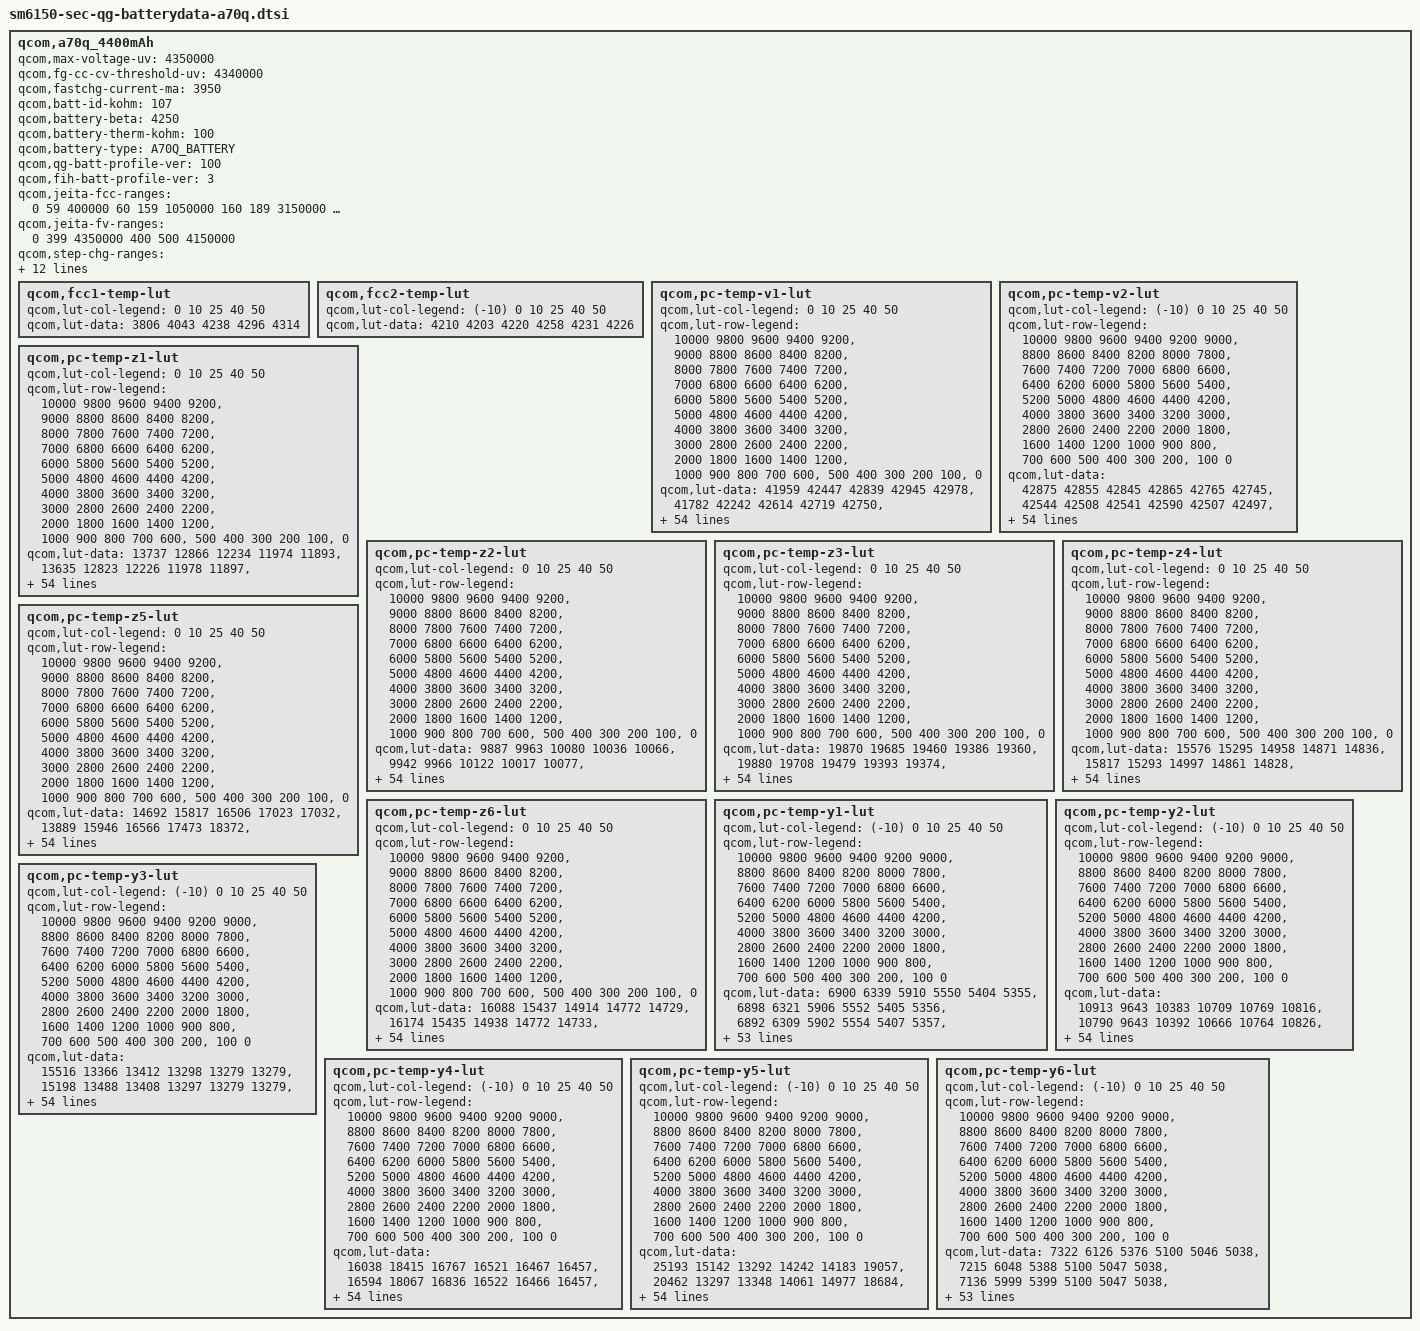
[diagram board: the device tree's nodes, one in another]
/*
 * Copyright (c) 2018, The Linux Foundation. All rights reserved.
 *
 * This program is free software; you can redistribute it and/or modify
 * it under the terms of the GNU General Public License version 2 and
 * only version 2 as published by the Free Software Foundation.
 *
 * This program is distributed in the hope that it will be useful,
 * but WITHOUT ANY WARRANTY; without even the implied warranty of
 * MERCHANTABILITY or FITNESS FOR A PARTICULAR PURPOSE.  See the
 * GNU General Public License for more details.
 */

qcom,a70q_4400mAh {
	/* A70Q BATTERY */
	qcom,max-voltage-uv = <4350000>;
	qcom,fg-cc-cv-threshold-uv = <4340000>;
	qcom,fastchg-current-ma = <3950>;
	qcom,batt-id-kohm = <107>;
	qcom,battery-beta = <4250>;
	qcom,battery-therm-kohm = <100>;
	qcom,battery-type = "A70Q_BATTERY";
	qcom,qg-batt-profile-ver = <100>;
	qcom,fih-batt-profile-ver = <3>;

	qcom,jeita-fcc-ranges = <0  59   400000
				60  159  1050000
				160 189  3150000
				190 399  3950000
				400 490  1550000>;

	qcom,jeita-fv-ranges = <0   399  4350000
				400 500  4150000>;

	qcom,step-chg-ranges = <3500000  4219999  3950000
				4220000  4350000  3150000>;
	qcom,vbat-avg-based-step-chg;
	qcom,taper-fcc;

	/* COOL = 18 DegC, WARM = 41 DegC */
	qcom,jeita-soft-thresholds = <0x4205 0x24EC>;
	/* COLD = 0 DegC, HOT = 50 DegC */
	qcom,jeita-hard-thresholds = <0x57F0 0x1C52>;

	qcom,qg-batt-aging-enable;
	qcom,vfloat-ranges = <0 299 4350000
				300 399 4330000
				400 699 4310000
				700 999 4290000
				1000 9999 4240000>;

	qcom,vbat-rechg-ranges = <0 299 4280000
				300 399 4260000
				400 699 4240000
				700 999 4220000
				1000 9999 4170000>;

	qcom,full-condition-soc-ranges = <0 299 93
				300 399 92
				400 699 91
				700 999 90
				1000 9999 89>;

	qcom,fcc1-temp-lut {
		qcom,lut-col-legend = <0 10 25 40 50>;
		qcom,lut-data = <3806 4043 4238 4296 4314>;
	};

	qcom,fcc2-temp-lut {
		qcom,lut-col-legend = <(-10) 0 10 25 40 50>;
		qcom,lut-data = <4210 4203 4220 4258 4231 4226>;
	};

	qcom,pc-temp-v1-lut {
		qcom,lut-col-legend = <0 10 25 40 50>;
		qcom,lut-row-legend = <10000 9800 9600 9400 9200>,
			<9000 8800 8600 8400 8200>,
			<8000 7800 7600 7400 7200>,
			<7000 6800 6600 6400 6200>,
			<6000 5800 5600 5400 5200>,
			<5000 4800 4600 4400 4200>,
			<4000 3800 3600 3400 3200>,
			<3000 2800 2600 2400 2200>,
			<2000 1800 1600 1400 1200>,
			<1000 900 800 700 600>,
			<500 400 300 200 100>,
			<0>;
		qcom,lut-data = <41959 42447 42839 42945 42978>,
			<41782 42242 42614 42719 42750>,
			<41605 42051 42393 42496 42527>,
			<41430 41866 42178 42277 42309>,
			<41272 41682 41975 42062 42094>,
			<41142 41495 41781 41853 41882>,
			<41010 41316 41590 41649 41673>,
			<40823 41160 41392 41445 41467>,
			<40498 41034 41201 41241 41260>,
			<40160 40886 41036 41051 41060>,
			<39964 40632 40896 40892 40881>,
			<39846 40279 40734 40742 40713>,
			<39750 40020 40462 40549 40533>,
			<39657 39890 40137 40280 40326>,
			<39574 39792 39938 40041 40124>,
			<39491 39699 39838 39900 39960>,
			<39398 39614 39751 39796 39820>,
			<39298 39525 39642 39679 39682>,
			<39197 39409 39522 39550 39549>,
			<39093 39263 39372 39406 39411>,
			<38987 39103 39143 39217 39232>,
			<38886 38914 38900 38983 39005>,
			<38791 38712 38754 38799 38813>,
			<38701 38582 38658 38678 38681>,
			<38615 38512 38575 38578 38573>,
			<38531 38461 38493 38485 38477>,
			<38450 38413 38417 38400 38390>,
			<38389 38370 38349 38323 38311>,
			<38343 38332 38287 38252 38237>,
			<38306 38298 38230 38187 38169>,
			<38278 38266 38181 38131 38109>,
			<38257 38238 38136 38080 38057>,
			<38239 38211 38097 38033 38008>,
			<38220 38187 38065 37994 37962>,
			<38203 38163 38036 37958 37919>,
			<38182 38142 38004 37917 37871>,
			<38151 38117 37973 37873 37818>,
			<38102 38074 37934 37823 37758>,
			<38036 37998 37872 37756 37687>,
			<37953 37906 37787 37672 37603>,
			<37839 37806 37692 37578 37507>,
			<37711 37688 37582 37469 37394>,
			<37565 37548 37453 37343 37265>,
			<37430 37396 37300 37188 37110>,
			<37320 37270 37170 37066 36996>,
			<37266 37192 37089 36989 36925>,
			<37275 37172 37067 36967 36905>,
			<37247 37151 37051 36953 36889>,
			<37221 37128 37032 36935 36870>,
			<37132 37062 36987 36886 36815>,
			<36846 36834 36767 36638 36540>,
			<36403 36395 36332 36205 36109>,
			<35851 35839 35775 35647 35549>,
			<35128 35098 35023 34888 34788>,
			<33884 33898 33847 33712 33611>,
			<30000 30000 30000 30000 30000>;
	};

	qcom,pc-temp-v2-lut {
		qcom,lut-col-legend = <(-10) 0 10 25 40 50>;
		qcom,lut-row-legend = <10000 9800 9600 9400 9200 9000>,
			<8800 8600 8400 8200 8000 7800>,
			<7600 7400 7200 7000 6800 6600>,
			<6400 6200 6000 5800 5600 5400>,
			<5200 5000 4800 4600 4400 4200>,
			<4000 3800 3600 3400 3200 3000>,
			<2800 2600 2400 2200 2000 1800>,
			<1600 1400 1200 1000 900 800>,
			<700 600 500 400 300 200>,
			<100 0>;
		qcom,lut-data = <42875 42855 42845 42865 42765 42745>,
			<42544 42508 42541 42590 42507 42497>,
			<42243 42183 42262 42333 42263 42260>,
			<41971 41871 42012 42098 42035 42034>,
			<41705 41526 41790 41884 41822 41820>,
			<41504 41298 41580 41677 41616 41612>,
			<41414 41268 41364 41464 41407 41405>,
			<41362 41258 41150 41253 41199 41201>,
			<41255 41231 40972 41067 41007 41005>,
			<40701 40914 40851 40922 40844 40816>,
			<40038 40439 40727 40770 40680 40630>,
			<39824 40122 40497 40544 40470 40433>,
			<39754 39879 40103 40240 40208 40225>,
			<39672 39686 39797 39998 39992 40040>,
			<39508 39548 39676 39848 39862 39893>,
			<39281 39434 39590 39726 39756 39763>,
			<39032 39306 39480 39610 39635 39628>,
			<38712 39164 39341 39504 39503 39493>,
			<38449 38998 39184 39384 39356 39346>,
			<38349 38754 39003 39210 39173 39166>,
			<38292 38424 38800 38998 38959 38956>,
			<38244 38216 38626 38809 38773 38772>,
			<38199 38144 38488 38640 38619 38620>,
			<38158 38096 38367 38494 38486 38488>,
			<38117 38055 38262 38383 38378 38379>,
			<38078 38019 38169 38291 38288 38288>,
			<38038 37987 38084 38208 38206 38204>,
			<37998 37958 38000 38132 38130 38127>,
			<37958 37929 37926 38061 38059 38055>,
			<37918 37899 37880 37996 37996 37990>,
			<37880 37868 37853 37935 37940 37932>,
			<37842 37837 37830 37880 37887 37877>,
			<37800 37804 37805 37831 37836 37825>,
			<37756 37768 37776 37786 37784 37775>,
			<37710 37730 37744 37741 37725 37712>,
			<37661 37689 37703 37699 37648 37615>,
			<37609 37642 37657 37652 37565 37508>,
			<37552 37588 37603 37593 37491 37423>,
			<37488 37522 37536 37523 37423 37353>,
			<37418 37449 37459 37448 37350 37281>,
			<37338 37369 37368 37368 37268 37198>,
			<37249 37279 37263 37276 37174 37106>,
			<37165 37184 37157 37156 37061 36997>,
			<37090 37081 37052 37014 36920 36859>,
			<37015 36978 36955 36923 36841 36782>,
			<36940 36882 36874 36873 36811 36756>,
			<36899 36834 36835 36856 36797 36744>,
			<36851 36784 36793 36838 36781 36728>,
			<36789 36725 36739 36808 36750 36697>,
			<36688 36633 36650 36742 36665 36584>,
			<36490 36449 36461 36529 36361 36259>,
			<36130 36113 36099 36083 35891 35776>,
			<35582 35592 35542 35490 35276 35150>,
			<34791 34837 34763 34688 34429 34282>,
			<33566 33623 33591 33442 33201 33031>,
			<28481 28300 28229 28279 28273 28212>;
	};

	qcom,pc-temp-z1-lut {
		qcom,lut-col-legend = <0 10 25 40 50>;
		qcom,lut-row-legend = <10000 9800 9600 9400 9200>,
			<9000 8800 8600 8400 8200>,
			<8000 7800 7600 7400 7200>,
			<7000 6800 6600 6400 6200>,
			<6000 5800 5600 5400 5200>,
			<5000 4800 4600 4400 4200>,
			<4000 3800 3600 3400 3200>,
			<3000 2800 2600 2400 2200>,
			<2000 1800 1600 1400 1200>,
			<1000 900 800 700 600>,
			<500 400 300 200 100>,
			<0>;
		qcom,lut-data = <13737 12866 12234 11974 11893>,
			<13635 12823 12226 11978 11897>,
			<13620 12826 12224 11976 11898>,
			<13612 12837 12223 11974 11899>,
			<13607 12841 12221 11973 11900>,
			<13604 12836 12219 11974 11901>,
			<13602 12827 12219 11974 11901>,
			<13592 12822 12221 11974 11901>,
			<13558 12821 12223 11974 11901>,
			<13522 12820 12223 11973 11901>,
			<13508 12813 12218 11972 11900>,
			<13502 12802 12213 11969 11898>,
			<13498 12796 12208 11966 11897>,
			<13500 12796 12202 11962 11896>,
			<13513 12797 12201 11960 11896>,
			<13529 12800 12205 11961 11896>,
			<13545 12812 12210 11965 11898>,
			<13564 12824 12215 11967 11899>,
			<13578 12830 12219 11969 11900>,
			<13582 12834 12222 11970 11902>,
			<13584 12838 12224 11972 11903>,
			<13586 12845 12226 11974 11905>,
			<13590 12855 12230 11977 11907>,
			<13597 12861 12236 11980 11910>,
			<13603 12866 12241 11983 11913>,
			<13608 12870 12244 11986 11916>,
			<13614 12872 12247 11989 11918>,
			<13621 12876 12251 11993 11920>,
			<13633 12878 12256 11996 11922>,
			<13644 12878 12260 11999 11925>,
			<13649 12878 12263 12002 11927>,
			<13648 12879 12266 12005 11929>,
			<13646 12882 12268 12008 11932>,
			<13647 12886 12269 12011 11934>,
			<13653 12892 12271 12014 11937>,
			<13661 12906 12273 12017 11940>,
			<13675 12918 12275 12019 11943>,
			<13708 12921 12279 12022 11946>,
			<13738 12922 12283 12025 11948>,
			<13741 12923 12287 12029 11951>,
			<13728 12926 12291 12032 11954>,
			<13713 12931 12296 12035 11957>,
			<13683 12940 12301 12038 11960>,
			<13675 12949 12306 12042 11962>,
			<13689 12951 12312 12044 11964>,
			<13676 12953 12311 12046 11964>,
			<13665 12951 12317 12045 11964>,
			<13678 12947 12309 12046 11965>,
			<13684 12949 12310 12049 11966>,
			<13684 12950 12316 12052 11970>,
			<13708 12966 12321 12058 11977>,
			<13722 12985 12332 12069 11986>,
			<13717 12989 12347 12080 11996>,
			<13719 13025 12376 12098 12012>,
			<13719 13025 12376 12098 12012>,
			<13719 13025 12376 12098 12012>;
	};

	qcom,pc-temp-z2-lut {
		qcom,lut-col-legend = <0 10 25 40 50>;
		qcom,lut-row-legend = <10000 9800 9600 9400 9200>,
			<9000 8800 8600 8400 8200>,
			<8000 7800 7600 7400 7200>,
			<7000 6800 6600 6400 6200>,
			<6000 5800 5600 5400 5200>,
			<5000 4800 4600 4400 4200>,
			<4000 3800 3600 3400 3200>,
			<3000 2800 2600 2400 2200>,
			<2000 1800 1600 1400 1200>,
			<1000 900 800 700 600>,
			<500 400 300 200 100>,
			<0>;
		qcom,lut-data = <9887 9963 10080 10036 10066>,
			<9942 9966 10122 10017 10077>,
			<9963 9968 10133 10021 10073>,
			<9977 9970 10144 10031 10059>,
			<9980 9972 10300 10034 10052>,
			<9969 9975 10734 10030 10054>,
			<9953 9980 10995 10026 10060>,
			<9947 9985 11036 10027 10067>,
			<9950 9994 11057 10030 10073>,
			<9953 10003 11045 10035 10078>,
			<9950 10019 10978 10047 10080>,
			<9936 10039 10913 10064 10087>,
			<9921 10050 10902 10067 10095>,
			<9915 10052 10846 10053 10103>,
			<9910 10053 10727 10040 10111>,
			<9907 10062 10376 10056 10116>,
			<9908 10093 10098 10092 10121>,
			<9915 10134 10106 10109 10127>,
			<9924 10169 10163 10113 10136>,
			<9938 10204 10223 10117 10148>,
			<9958 10233 10285 10147 10163>,
			<9978 10254 10335 10217 10186>,
			<9994 10272 10334 10248 10197>,
			<10009 10277 10287 10200 10186>,
			<10026 10273 10254 10129 10159>,
			<10046 10267 10259 10091 10125>,
			<10067 10262 10267 10066 10063>,
			<10081 10258 10268 10051 10025>,
			<10090 10256 10264 10046 10025>,
			<10097 10257 10261 10044 10027>,
			<10105 10262 10265 10048 10030>,
			<10113 10268 10274 10059 10034>,
			<10121 10277 10285 10075 10042>,
			<10132 10289 10302 10098 10058>,
			<10147 10300 10323 10128 10089>,
			<10163 10309 10342 10158 10124>,
			<10181 10319 10362 10188 10175>,
			<10204 10332 10380 10215 10215>,
			<10223 10349 10400 10243 10224>,
			<10230 10359 10419 10277 10230>,
			<10232 10353 10422 10293 10232>,
			<10235 10340 10410 10287 10228>,
			<10238 10335 10402 10279 10225>,
			<10271 10333 10399 10274 10229>,
			<10306 10384 10407 10279 10225>,
			<10057 10377 10396 10267 10210>,
			<9392 10373 10375 10258 10215>,
			<9394 10373 10363 10276 10222>,
			<9469 10378 10360 10282 10225>,
			<9471 10398 10367 10324 10297>,
			<9740 10400 10386 10273 10143>,
			<9904 10347 10313 10175 10061>,
			<9751 10299 10272 10136 10021>,
			<9389 10237 10198 10083 9975>,
			<9389 10237 10198 10083 9975>,
			<9389 10237 10198 10083 9975>;
	};

	qcom,pc-temp-z3-lut {
		qcom,lut-col-legend = <0 10 25 40 50>;
		qcom,lut-row-legend = <10000 9800 9600 9400 9200>,
			<9000 8800 8600 8400 8200>,
			<8000 7800 7600 7400 7200>,
			<7000 6800 6600 6400 6200>,
			<6000 5800 5600 5400 5200>,
			<5000 4800 4600 4400 4200>,
			<4000 3800 3600 3400 3200>,
			<3000 2800 2600 2400 2200>,
			<2000 1800 1600 1400 1200>,
			<1000 900 800 700 600>,
			<500 400 300 200 100>,
			<0>;
		qcom,lut-data = <19870 19685 19460 19386 19360>,
			<19880 19708 19479 19393 19374>,
			<19872 19703 19482 19398 19379>,
			<19860 19689 19485 19402 19383>,
			<19844 19678 19492 19403 19385>,
			<19806 19671 19503 19399 19383>,
			<19763 19663 19509 19393 19377>,
			<19749 19647 19507 19390 19374>,
			<19750 19612 19503 19390 19373>,
			<19752 19586 19498 19389 19372>,
			<19746 19591 19490 19383 19368>,
			<19720 19609 19484 19373 19361>,
			<19689 19618 19482 19372 19359>,
			<19672 19605 19480 19382 19361>,
			<19658 19580 19472 19389 19364>,
			<19650 19561 19438 19382 19362>,
			<19653 19543 19409 19367 19357>,
			<19668 19531 19408 19362 19354>,
			<19684 19534 19414 19362 19352>,
			<19696 19552 19423 19363 19350>,
			<19708 19568 19440 19368 19351>,
			<19715 19579 19457 19378 19358>,
			<19714 19587 19458 19385 19367>,
			<19712 19590 19446 19390 19380>,
			<19712 19588 19438 19394 19394>,
			<19713 19584 19444 19396 19396>,
			<19715 19581 19455 19398 19392>,
			<19716 19579 19460 19399 19389>,
			<19712 19577 19462 19398 19386>,
			<19703 19575 19463 19396 19384>,
			<19694 19573 19463 19394 19380>,
			<19684 19571 19460 19392 19374>,
			<19674 19569 19457 19389 19368>,
			<19664 19567 19453 19384 19362>,
			<19655 19565 19450 19379 19356>,
			<19647 19561 19447 19376 19354>,
			<19640 19556 19444 19373 19353>,
			<19635 19553 19442 19372 19353>,
			<19631 19551 19440 19372 19353>,
			<19626 19548 19438 19374 19355>,
			<19622 19545 19436 19375 19357>,
			<19618 19542 19433 19372 19359>,
			<19615 19537 19430 19370 19361>,
			<19590 19530 19425 19372 19364>,
			<19555 19496 19414 19365 19359>,
			<19483 19493 19411 19361 19353>,
			<19288 19484 19407 19359 19342>,
			<19287 19482 19399 19352 19339>,
			<19274 19482 19398 19349 19337>,
			<19274 19477 19393 19345 19329>,
			<19380 19476 19393 19358 19356>,
			<19466 19486 19397 19367 19361>,
			<19457 19488 19403 19367 19361>,
			<19361 19469 19406 19368 19361>,
			<19361 19469 19406 19368 19361>,
			<19361 19469 19406 19368 19361>;
	};

	qcom,pc-temp-z4-lut {
		qcom,lut-col-legend = <0 10 25 40 50>;
		qcom,lut-row-legend = <10000 9800 9600 9400 9200>,
			<9000 8800 8600 8400 8200>,
			<8000 7800 7600 7400 7200>,
			<7000 6800 6600 6400 6200>,
			<6000 5800 5600 5400 5200>,
			<5000 4800 4600 4400 4200>,
			<4000 3800 3600 3400 3200>,
			<3000 2800 2600 2400 2200>,
			<2000 1800 1600 1400 1200>,
			<1000 900 800 700 600>,
			<500 400 300 200 100>,
			<0>;
		qcom,lut-data = <15576 15295 14958 14871 14836>,
			<15817 15293 14997 14861 14828>,
			<15751 15219 14954 14843 14814>,
			<15626 15113 14889 14814 14794>,
			<15513 15041 14829 14790 14773>,
			<15405 15000 14764 14771 14758>,
			<15308 14965 14729 14756 14745>,
			<15258 14920 14722 14748 14737>,
			<15238 14861 14716 14745 14732>,
			<15222 14822 14704 14740 14727>,
			<15192 14829 14677 14727 14717>,
			<15140 14853 14659 14710 14703>,
			<15085 14866 14675 14707 14698>,
			<15049 14850 14714 14719 14702>,
			<15023 14821 14732 14729 14706>,
			<14999 14801 14732 14718 14701>,
			<14967 14785 14726 14691 14685>,
			<14929 14775 14718 14678 14674>,
			<14899 14776 14710 14674 14668>,
			<14883 14786 14708 14671 14664>,
			<14872 14803 14778 14701 14683>,
			<14866 14859 14872 14787 14761>,
			<14870 14949 14888 14828 14807>,
			<14880 14984 14881 14814 14789>,
			<14890 14971 14870 14792 14757>,
			<14903 14948 14848 14774 14739>,
			<14917 14928 14817 14756 14728>,
			<14922 14910 14796 14741 14719>,
			<14922 14893 14781 14732 14712>,
			<14922 14879 14771 14724 14705>,
			<14921 14867 14767 14718 14699>,
			<14916 14858 14764 14712 14694>,
			<14907 14851 14763 14709 14691>,
			<14899 14845 14763 14707 14689>,
			<14890 14841 14764 14707 14688>,
			<14881 14836 14765 14707 14688>,
			<14872 14834 14766 14712 14694>,
			<14863 14835 14768 14718 14701>,
			<14856 14842 14773 14723 14706>,
			<14856 14847 14778 14729 14711>,
			<14861 14843 14778 14730 14712>,
			<14863 14833 14768 14723 14706>,
			<14854 14826 14759 14720 14703>,
			<14828 14814 14754 14722 14711>,
			<14802 14774 14727 14708 14697>,
			<14867 14763 14711 14694 14684>,
			<15062 14759 14705 14686 14681>,
			<15057 14751 14697 14675 14666>,
			<15055 14744 14687 14659 14649>,
			<15050 14750 14689 14659 14649>,
			<14971 14766 14708 14677 14666>,
			<14905 14772 14714 14676 14668>,
			<14931 14776 14710 14677 14669>,
			<15036 14789 14712 14678 14669>,
			<15036 14789 14712 14678 14669>,
			<15036 14789 14712 14678 14669>;
	};

	qcom,pc-temp-z5-lut {
		qcom,lut-col-legend = <0 10 25 40 50>;
		qcom,lut-row-legend = <10000 9800 9600 9400 9200>,
			<9000 8800 8600 8400 8200>,
			<8000 7800 7600 7400 7200>,
			<7000 6800 6600 6400 6200>,
			<6000 5800 5600 5400 5200>,
			<5000 4800 4600 4400 4200>,
			<4000 3800 3600 3400 3200>,
			<3000 2800 2600 2400 2200>,
			<2000 1800 1600 1400 1200>,
			<1000 900 800 700 600>,
			<500 400 300 200 100>,
			<0>;
		qcom,lut-data = <14692 15817 16506 17023 17032>,
			<13889 15946 16566 17473 18372>,
			<14180 16341 17183 18096 19180>,
			<14666 16968 18090 18900 19927>,
			<14894 17614 19423 19326 20440>,
			<14913 18461 21458 19344 20549>,
			<14927 19176 22989 19341 20597>,
			<15019 19231 23616 19450 20744>,
			<15538 18882 24168 19816 21253>,
			<16096 18608 25553 20049 21672>,
			<16166 19322 28813 19791 21505>,
			<15899 21088 30995 19426 20981>,
			<15595 21979 30046 19665 20813>,
			<15441 21486 27269 21476 21565>,
			<15326 20778 24488 23037 22600>,
			<15260 20543 20990 22765 23531>,
			<15510 20491 18559 21927 24968>,
			<16650 20465 19139 22131 26458>,
			<18199 22053 21714 23880 28089>,
			<20090 28136 24917 25298 29366>,
			<22597 33087 29952 25282 28689>,
			<24693 34533 34705 24907 25359>,
			<25899 35446 33770 24232 22924>,
			<26845 35593 25601 21630 22124>,
			<27812 33045 19878 18792 21590>,
			<29272 29495 20166 18526 21468>,
			<30819 27936 21056 19217 21671>,
			<31423 27127 22022 20077 22021>,
			<30898 26715 23480 21005 22961>,
			<29880 26783 25144 22099 24258>,
			<28867 27117 26679 23279 24630>,
			<27724 27555 28201 24649 24576>,
			<26615 28265 29163 25708 24531>,
			<25954 29124 29942 26313 24773>,
			<25501 29566 30546 26751 25286>,
			<25205 29702 30591 26869 25532>,
			<25228 29727 30284 26548 25603>,
			<25709 29681 29822 26138 25638>,
			<26184 29501 28954 25736 25215>,
			<26167 29239 27722 25023 24024>,
			<25817 28599 26763 24295 23518>,
			<25649 27505 26080 23186 23869>,
			<25951 26652 25165 22454 24150>,
			<25567 25854 23718 22241 24165>,
			<24417 25019 24047 21548 23475>,
			<20897 24776 24087 20757 21087>,
			<11546 23078 23549 20818 18766>,
			<11525 23046 22289 20274 19403>,
			<11492 23418 22848 21964 22319>,
			<11532 22670 21481 21189 20883>,
			<15199 20831 19017 19467 22135>,
			<16495 20010 18076 19395 20831>,
			<14943 19306 18242 18468 19442>,
			<12048 16812 17864 17705 17987>,
			<12048 16812 17864 17705 17987>,
			<12048 16812 17864 17705 17987>;
	};

	qcom,pc-temp-z6-lut {
		qcom,lut-col-legend = <0 10 25 40 50>;
		qcom,lut-row-legend = <10000 9800 9600 9400 9200>,
			<9000 8800 8600 8400 8200>,
			<8000 7800 7600 7400 7200>,
			<7000 6800 6600 6400 6200>,
			<6000 5800 5600 5400 5200>,
			<5000 4800 4600 4400 4200>,
			<4000 3800 3600 3400 3200>,
			<3000 2800 2600 2400 2200>,
			<2000 1800 1600 1400 1200>,
			<1000 900 800 700 600>,
			<500 400 300 200 100>,
			<0>;
		qcom,lut-data = <16088 15437 14914 14772 14729>,
			<16174 15435 14938 14772 14733>,
			<16131 15392 14919 14766 14731>,
			<16049 15328 14891 14756 14725>,
			<15969 15281 14868 14746 14717>,
			<15886 15252 14847 14736 14709>,
			<15804 15226 14834 14726 14701>,
			<15748 15189 14828 14721 14696>,
			<15713 15136 14824 14719 14693>,
			<15683 15101 14815 14716 14690>,
			<15646 15103 14796 14707 14683>,
			<15599 15114 14784 14693 14673>,
			<15559 15120 14790 14691 14669>,
			<15540 15106 14802 14700 14672>,
			<15527 15080 14805 14708 14674>,
			<15520 15063 14786 14699 14671>,
			<15517 15050 14767 14680 14662>,
			<15515 15042 14766 14672 14655>,
			<15514 15044 14767 14671 14651>,
			<15516 15058 14770 14670 14649>,
			<15521 15078 14809 14685 14658>,
			<15527 15111 14860 14729 14697>,
			<15533 15154 14868 14750 14720>,
			<15539 15171 14861 14747 14719>,
			<15547 15165 14853 14741 14715>,
			<15557 15156 14847 14736 14710>,
			<15568 15148 14841 14730 14704>,
			<15572 15142 14836 14725 14698>,
			<15571 15136 14833 14720 14694>,
			<15570 15130 14830 14716 14690>,
			<15568 15125 14827 14713 14686>,
			<15563 15122 14825 14709 14680>,
			<15557 15119 14824 14706 14676>,
			<15552 15117 14823 14703 14671>,
			<15547 15116 14822 14700 14668>,
			<15543 15115 14822 14699 14667>,
			<15540 15114 14822 14700 14668>,
			<15537 15115 14822 14702 14671>,
			<15535 15120 14824 14705 14674>,
			<15535 15123 14827 14708 14677>,
			<15539 15122 14827 14710 14679>,
			<15540 15120 14822 14706 14678>,
			<15538 15118 14818 14704 14678>,
			<15523 15114 14815 14707 14683>,
			<15504 15091 14801 14698 14675>,
			<15495 15086 14793 14690 14666>,
			<15478 15081 14789 14685 14659>,
			<15476 15077 14782 14677 14652>,
			<15477 15077 14778 14669 14643>,
			<15481 15081 14778 14667 14639>,
			<15508 15093 14789 14684 14662>,
			<15533 15110 14797 14691 14668>,
			<15553 15126 14804 14694 14672>,
			<15581 15140 14813 14700 14675>,
			<15581 15140 14813 14700 14675>,
			<15581 15140 14813 14700 14675>;
	};

	qcom,pc-temp-y1-lut {
		qcom,lut-col-legend = <(-10) 0 10 25 40 50>;
		qcom,lut-row-legend = <10000 9800 9600 9400 9200 9000>,
			<8800 8600 8400 8200 8000 7800>,
			<7600 7400 7200 7000 6800 6600>,
			<6400 6200 6000 5800 5600 5400>,
			<5200 5000 4800 4600 4400 4200>,
			<4000 3800 3600 3400 3200 3000>,
			<2800 2600 2400 2200 2000 1800>,
			<1600 1400 1200 1000 900 800>,
			<700 600 500 400 300 200>,
			<100 0>;
		qcom,lut-data = <6900 6339 5910 5550 5404 5355>,
			<6898 6321 5906 5552 5405 5356>,
			<6892 6309 5902 5554 5407 5357>,
			<6883 6302 5899 5555 5407 5358>,
			<6874 6300 5897 5555 5408 5358>,
			<6868 6300 5896 5556 5408 5358>,
			<6864 6304 5898 5555 5407 5357>,
			<6858 6314 5902 5555 5406 5356>,
			<6857 6319 5903 5554 5405 5355>,
			<6866 6319 5903 5554 5403 5354>,
			<6877 6318 5903 5554 5402 5354>,
			<6876 6319 5907 5555 5402 5354>,
			<6867 6322 5917 5556 5402 5355>,
			<6859 6327 5923 5557 5402 5355>,
			<6860 6336 5921 5558 5402 5355>,
			<6863 6347 5917 5560 5402 5355>,
			<6866 6350 5917 5560 5403 5354>,
			<6876 6345 5915 5560 5402 5354>,
			<6883 6340 5914 5560 5402 5355>,
			<6880 6341 5917 5561 5403 5355>,
			<6870 6350 5926 5563 5404 5356>,
			<6866 6356 5930 5565 5405 5356>,
			<6869 6364 5928 5567 5406 5357>,
			<6875 6370 5925 5570 5408 5358>,
			<6888 6368 5927 5572 5410 5360>,
			<6923 6358 5934 5574 5411 5361>,
			<6949 6352 5941 5576 5413 5363>,
			<6931 6355 5946 5579 5415 5364>,
			<6897 6362 5949 5582 5418 5366>,
			<6883 6365 5951 5585 5420 5368>,
			<6878 6365 5953 5589 5423 5371>,
			<6874 6366 5955 5592 5427 5373>,
			<6871 6367 5954 5594 5429 5376>,
			<6868 6368 5952 5596 5432 5378>,
			<6865 6369 5953 5599 5435 5380>,
			<6863 6366 5962 5603 5438 5382>,
			<6862 6365 5970 5607 5441 5384>,
			<6864 6367 5969 5608 5444 5386>,
			<6871 6365 5962 5610 5446 5389>,
			<6874 6362 5957 5612 5447 5391>,
			<6869 6362 5960 5615 5448 5392>,
			<6862 6362 5964 5619 5448 5394>,
			<6863 6363 5964 5624 5449 5396>,
			<6884 6365 5962 5631 5454 5398>,
			<6888 6367 5962 5632 5460 5401>,
			<6860 6372 5964 5632 5465 5404>,
			<6857 6374 5965 5633 5466 5404>,
			<6866 6376 5968 5634 5466 5404>,
			<6892 6377 5974 5637 5463 5403>,
			<6893 6386 5975 5641 5463 5403>,
			<6883 6422 5981 5639 5466 5406>,
			<6909 6403 5988 5644 5474 5413>,
			<6935 6427 6003 5658 5483 5421>,
			<6933 6438 6021 5677 5495 5431>,
			<6933 6438 6021 5677 5495 5431>,
			<6933 6438 6021 5677 5495 5431>;
	};

	qcom,pc-temp-y2-lut {
		qcom,lut-col-legend = <(-10) 0 10 25 40 50>;
		qcom,lut-row-legend = <10000 9800 9600 9400 9200 9000>,
			<8800 8600 8400 8200 8000 7800>,
			<7600 7400 7200 7000 6800 6600>,
			<6400 6200 6000 5800 5600 5400>,
			<5200 5000 4800 4600 4400 4200>,
			<4000 3800 3600 3400 3200 3000>,
			<2800 2600 2400 2200 2000 1800>,
			<1600 1400 1200 1000 900 800>,
			<700 600 500 400 300 200>,
			<100 0>;
		qcom,lut-data = <10913 9643 10383 10709 10769 10816>,
			<10790 9643 10392 10666 10764 10826>,
			<10504 9841 10398 10632 10757 10829>,
			<10157 10222 10400 10607 10749 10826>,
			<9851 10476 10400 10591 10742 10819>,
			<9688 10588 10398 10584 10736 10809>,
			<9682 10506 10381 10588 10731 10791>,
			<9685 10279 10343 10602 10726 10763>,
			<9686 10177 10331 10608 10717 10750>,
			<9678 10263 10439 10614 10677 10748>,
			<9666 10402 10568 10620 10633 10748>,
			<9663 10506 10576 10622 10641 10749>,
			<9662 10586 10536 10627 10696 10753>,
			<9661 10690 10510 10635 10729 10758>,
			<9660 10952 10553 10661 10715 10764>,
			<9659 11298 10641 10701 10692 10770>,
			<9659 11346 10709 10738 10686 10769>,
			<9658 10616 10758 10778 10704 10746>,
			<9657 9854 10802 10814 10725 10725>,
			<9657 9738 10841 10843 10748 10739>,
			<9657 9709 10876 10868 10785 10785>,
			<9656 9695 10921 10895 10817 10828>,
			<9656 9687 11010 10926 10846 10868>,
			<9656 9681 11092 10960 10876 10903>,
			<9656 9677 11096 10990 10904 10918>,
			<9656 9673 11050 11019 10933 10924>,
			<9655 9670 10990 11057 10965 10929>,
			<9655 9667 10915 11118 11001 10947>,
			<9655 9665 10830 11185 11039 10982>,
			<9655 9663 10774 11238 11068 11012>,
			<9655 9661 10732 11287 11090 11038>,
			<9655 9660 10709 11309 11114 11064>,
			<9655 9660 10705 11308 11158 11097>,
			<9655 9659 10637 11305 11223 11134>,
			<9655 9659 10511 11295 11252 11151>,
			<9655 9658 10229 11257 11234 11152>,
			<9655 9657 9925 11213 11208 11150>,
			<9655 9657 9807 11178 11195 11144>,
			<9655 9657 9746 11147 11187 11134>,
			<9655 9657 9715 11123 11187 11121>,
			<9655 9656 9702 11104 11184 11095>,
			<9655 9656 9693 11082 11170 11066>,
			<9655 9656 9686 11043 11162 11058>,
			<9654 9655 9679 10985 11162 11068>,
			<9654 9655 9674 10916 11139 11053>,
			<9654 9655 9671 10847 11038 10937>,
			<9654 9655 9670 10820 11024 10878>,
			<9654 9654 9670 10809 11029 10843>,
			<9654 9654 9672 10819 11019 10845>,
			<9654 9655 9673 10826 11047 10827>,
			<9654 9655 9672 10807 10958 10818>,
			<9654 9654 9670 10729 10899 10777>,
			<9654 9654 9665 10639 10834 10685>,
			<9654 9654 9661 10558 10710 10553>,
			<9654 9654 9661 10558 10710 10553>,
			<9654 9654 9661 10558 10710 10553>;
	};

	qcom,pc-temp-y3-lut {
		qcom,lut-col-legend = <(-10) 0 10 25 40 50>;
		qcom,lut-row-legend = <10000 9800 9600 9400 9200 9000>,
			<8800 8600 8400 8200 8000 7800>,
			<7600 7400 7200 7000 6800 6600>,
			<6400 6200 6000 5800 5600 5400>,
			<5200 5000 4800 4600 4400 4200>,
			<4000 3800 3600 3400 3200 3000>,
			<2800 2600 2400 2200 2000 1800>,
			<1600 1400 1200 1000 900 800>,
			<700 600 500 400 300 200>,
			<100 0>;
		qcom,lut-data = <15516 13366 13412 13298 13279 13279>,
			<15198 13488 13408 13297 13279 13279>,
			<14732 13564 13406 13297 13280 13278>,
			<14234 13606 13408 13297 13282 13278>,
			<13821 13622 13410 13297 13283 13279>,
			<13608 13626 13414 13297 13283 13279>,
			<13628 13593 13420 13298 13283 13279>,
			<13701 13509 13429 13299 13283 13279>,
			<13731 13472 13432 13301 13283 13279>,
			<13632 13536 13426 13308 13286 13280>,
			<13509 13616 13415 13314 13290 13281>,
			<13499 13617 13405 13312 13289 13281>,
			<13550 13553 13393 13303 13285 13281>,
			<13607 13494 13386 13299 13283 13281>,
			<13651 13472 13389 13303 13284 13281>,
			<13693 13457 13394 13309 13287 13282>,
			<13715 13436 13395 13312 13289 13282>,
			<13725 13404 13390 13314 13291 13284>,
			<13735 13372 13383 13315 13293 13285>,
			<13763 13350 13374 13313 13292 13284>,
			<13821 13330 13362 13308 13288 13282>,
			<13880 13323 13351 13304 13285 13280>,
			<13929 13332 13341 13300 13283 13279>,
			<13978 13353 13331 13297 13280 13278>,
			<14029 13374 13323 13296 13280 13278>,
			<14081 13399 13315 13296 13280 13277>,
			<14134 13428 13309 13295 13280 13277>,
			<14188 13465 13304 13295 13280 13277>,
			<14241 13510 13299 13294 13280 13277>,
			<14292 13555 13299 13293 13280 13277>,
			<14343 13599 13305 13291 13280 13276>,
			<14391 13644 13313 13290 13281 13276>,
			<14434 13695 13319 13289 13281 13277>,
			<14473 13752 13326 13289 13281 13278>,
			<14511 13807 13328 13289 13281 13279>,
			<14549 13857 13326 13290 13279 13277>,
			<14587 13907 13322 13290 13278 13275>,
			<14628 13963 13324 13290 13278 13275>,
			<14670 14026 13341 13291 13278 13275>,
			<14713 14093 13362 13292 13278 13276>,
			<14757 14162 13377 13294 13278 13276>,
			<14802 14234 13392 13298 13279 13277>,
			<14856 14311 13413 13299 13279 13277>,
			<14920 14395 13442 13300 13279 13277>,
			<14999 14482 13477 13303 13280 13277>,
			<15105 14570 13522 13308 13284 13281>,
			<15169 14613 13553 13313 13287 13284>,
			<15250 14659 13591 13316 13290 13287>,
			<15297 14679 13601 13319 13293 13289>,
			<15292 14599 13590 13326 13294 13287>,
			<15370 14590 13598 13325 13289 13283>,
			<15495 14688 13617 13325 13290 13284>,
			<15638 14834 13676 13336 13294 13288>,
			<15860 15038 13782 13349 13299 13292>,
			<15860 15038 13782 13349 13299 13292>,
			<15860 15038 13782 13349 13299 13292>;
	};

	qcom,pc-temp-y4-lut {
		qcom,lut-col-legend = <(-10) 0 10 25 40 50>;
		qcom,lut-row-legend = <10000 9800 9600 9400 9200 9000>,
			<8800 8600 8400 8200 8000 7800>,
			<7600 7400 7200 7000 6800 6600>,
			<6400 6200 6000 5800 5600 5400>,
			<5200 5000 4800 4600 4400 4200>,
			<4000 3800 3600 3400 3200 3000>,
			<2800 2600 2400 2200 2000 1800>,
			<1600 1400 1200 1000 900 800>,
			<700 600 500 400 300 200>,
			<100 0>;
		qcom,lut-data = <16038 18415 16767 16521 16467 16457>,
			<16594 18067 16836 16522 16466 16457>,
			<17563 17850 16890 16524 16465 16456>,
			<18659 17733 16929 16527 16465 16456>,
			<19596 17685 16954 16530 16466 16456>,
			<20087 17675 16965 16533 16466 16457>,
			<20091 17940 16955 16536 16468 16458>,
			<20026 18635 16928 16539 16471 16459>,
			<19908 18939 16923 16545 16476 16461>,
			<19266 18387 17118 16563 16491 16463>,
			<18515 17674 17351 16580 16506 16465>,
			<18349 17519 17313 16578 16506 16468>,
			<18323 17497 17011 16565 16495 16470>,
			<18286 17493 16815 16558 16488 16473>,
			<18130 17539 16900 16569 16493 16478>,
			<17845 17615 17048 16591 16504 16485>,
			<17546 17639 17089 16614 16518 16496>,
			<17158 17623 17079 16646 16541 16515>,
			<16880 17589 17062 16665 16557 16529>,
			<16862 17413 16999 16654 16550 16524>,
			<16870 16968 16870 16624 16527 16508>,
			<16880 16735 16786 16593 16507 16493>,
			<16890 16736 16754 16543 16484 16475>,
			<16902 16738 16732 16506 16467 16460>,
			<16917 16744 16709 16504 16465 16458>,
			<16937 16761 16686 16504 16466 16459>,
			<16959 16784 16660 16504 16467 16460>,
			<16982 16808 16619 16507 16470 16463>,
			<17007 16836 16576 16513 16476 16468>,
			<17030 16870 16566 16519 16483 16473>,
			<17051 16917 16579 16525 16491 16481>,
			<17072 16965 16599 16528 16500 16490>,
			<17094 16999 16621 16525 16507 16499>,
			<17116 17029 16650 16521 16513 16508>,
			<17138 17062 16685 16519 16514 16510>,
			<17159 17103 16736 16519 16494 16490>,
			<17178 17145 16790 16519 16472 16466>,
			<17189 17176 16817 16519 16469 16462>,
			<17197 17197 16832 16520 16470 16464>,
			<17203 17219 16846 16523 16472 16466>,
			<17207 17249 16859 16535 16476 16469>,
			<17211 17286 16875 16550 16482 16473>,
			<17219 17330 16898 16558 16482 16472>,
			<17253 17384 16938 16564 16476 16462>,
			<17305 17459 17011 16574 16476 16459>,
			<17382 17592 17179 16602 16495 16481>,
			<17426 17665 17294 16629 16515 16506>,
			<17470 17736 17419 16656 16553 16551>,
			<17470 17761 17436 16684 16586 16589>,
			<17365 17601 17370 16741 16599 16563>,
			<17324 17514 17370 16731 16518 16492>,
			<17309 17495 17336 16686 16515 16487>,
			<17308 17468 17329 16707 16535 16500>,
			<17371 17496 17424 16766 16582 16538>,
			<17371 17496 17424 16766 16582 16538>,
			<17371 17496 17424 16766 16582 16538>;
	};

	qcom,pc-temp-y5-lut {
		qcom,lut-col-legend = <(-10) 0 10 25 40 50>;
		qcom,lut-row-legend = <10000 9800 9600 9400 9200 9000>,
			<8800 8600 8400 8200 8000 7800>,
			<7600 7400 7200 7000 6800 6600>,
			<6400 6200 6000 5800 5600 5400>,
			<5200 5000 4800 4600 4400 4200>,
			<4000 3800 3600 3400 3200 3000>,
			<2800 2600 2400 2200 2000 1800>,
			<1600 1400 1200 1000 900 800>,
			<700 600 500 400 300 200>,
			<100 0>;
		qcom,lut-data = <25193 15142 13292 14242 14183 19057>,
			<20462 13297 13348 14061 14977 18684>,
			<16565 12060 13382 13886 15475 18307>,
			<13591 11315 13400 13728 15741 17929>,
			<11631 10943 13407 13596 15839 17555>,
			<10777 10827 13406 13500 15836 17189>,
			<11453 10982 13169 13433 15543 16809>,
			<13275 11562 12582 13390 14894 16425>,
			<14053 12426 12343 13417 14643 16150>,
			<12818 14868 12741 13633 14957 15996>,
			<11287 17441 13225 13841 15319 15850>,
			<11311 17284 13271 13682 15127 15541>,
			<12691 14569 13112 13112 14199 14988>,
			<14256 12649 13001 12816 13629 14599>,
			<15708 12948 13195 13045 13856 14404>,
			<17058 13651 13657 13441 14240 14243>,
			<17144 14183 14225 13699 14415 14208>,
			<14267 14617 15169 13870 14478 14246>,
			<11440 14898 15860 14116 14560 14319>,
			<11148 14369 15895 15015 15092 14730>,
			<11108 12561 15884 16345 16217 15667>,
			<11097 11456 15854 16869 16823 16445>,
			<11144 11313 15505 17017 16809 17230>,
			<11213 11234 15068 17089 16654 17885>,
			<11238 11227 15257 17073 16604 17937>,
			<11249 11246 16546 16999 16608 17640>,
			<11254 11277 17464 16952 16563 17240>,
			<11247 11346 16175 16896 16252 16699>,
			<11232 11452 13917 16815 15842 16061>,
			<11234 11487 13273 16732 15794 15691>,
			<11330 11392 13571 16675 16226 15497>,
			<11432 11301 13965 16720 16789 15496>,
			<11441 11319 14266 17226 17315 16131>,
			<11431 11377 14281 17895 17849 17370>,
			<11425 11406 13892 18030 18031 17905>,
			<11427 11386 13181 17862 17834 17654>,
			<11434 11343 12462 17595 17530 17206>,
			<11452 11319 12197 17104 17270 16966>,
			<11508 11315 12115 16463 16998 16773>,
			<11551 11311 12039 16226 16696 16631>,
			<11512 11286 11887 16198 16288 16539>,
			<11408 11232 11717 16174 15887 16473>,
			<11328 11177 11597 15962 15845 16558>,
			<11277 11113 11477 15392 16286 16970>,
			<11256 11080 11323 14796 16501 16872>,
			<11292 11076 11151 14244 16007 15933>,
			<11341 11080 11146 13980 15749 15728>,
			<11490 11148 11209 13853 15510 15325>,
			<11846 11420 11622 14099 15158 14812>,
			<12488 12239 12620 14498 15376 14534>,
			<12651 12736 13017 14566 16266 15465>,
			<12204 12736 12776 14596 16532 15499>,
			<11628 12291 12149 14637 17293 16790>,
			<11283 11685 11411 14441 17552 17705>,
			<11283 11685 11411 14441 17552 17705>,
			<11283 11685 11411 14441 17552 17705>;
	};

	qcom,pc-temp-y6-lut {
		qcom,lut-col-legend = <(-10) 0 10 25 40 50>;
		qcom,lut-row-legend = <10000 9800 9600 9400 9200 9000>,
			<8800 8600 8400 8200 8000 7800>,
			<7600 7400 7200 7000 6800 6600>,
			<6400 6200 6000 5800 5600 5400>,
			<5200 5000 4800 4600 4400 4200>,
			<4000 3800 3600 3400 3200 3000>,
			<2800 2600 2400 2200 2000 1800>,
			<1600 1400 1200 1000 900 800>,
			<700 600 500 400 300 200>,
			<100 0>;
		qcom,lut-data = <7322 6126 5376 5100 5046 5038>,
			<7215 6048 5388 5100 5047 5038>,
			<7136 5999 5399 5100 5047 5038>,
			<7084 5973 5409 5101 5048 5038>,
			<7053 5963 5416 5102 5048 5038>,
			<7041 5960 5420 5103 5049 5038>,
			<7058 6014 5418 5104 5050 5039>,
			<7102 6153 5414 5106 5051 5039>,
			<7115 6215 5414 5109 5052 5040>,
			<6886 6117 5461 5118 5059 5041>,
			<6603 5977 5517 5127 5065 5042>,
			<6567 5910 5502 5125 5065 5043>,
			<6610 5868 5407 5115 5059 5044>,
			<6639 5848 5345 5110 5055 5045>,
			<6624 5859 5371 5116 5058 5046>,
			<6586 5878 5416 5126 5063 5049>,
			<6537 5883 5429 5136 5069 5052>,
			<6449 5868 5423 5146 5076 5059>,
			<6380 5840 5413 5151 5082 5064>,
			<6390 5782 5390 5147 5079 5062>,
			<6442 5680 5346 5134 5070 5055>,
			<6493 5629 5316 5122 5061 5049>,
			<6532 5655 5302 5105 5053 5042>,
			<6571 5704 5292 5093 5046 5037>,
			<6612 5748 5284 5093 5045 5037>,
			<6658 5788 5276 5093 5046 5037>,
			<6703 5832 5270 5093 5046 5037>,
			<6748 5882 5264 5094 5047 5038>,
			<6793 5937 5259 5096 5049 5039>,
			<6835 5993 5260 5098 5051 5041>,
			<6876 6049 5277 5100 5054 5043>,
			<6916 6105 5304 5101 5057 5045>,
			<6954 6160 5330 5101 5060 5049>,
			<6991 6214 5360 5101 5062 5052>,
			<7026 6268 5390 5101 5062 5053>,
			<7059 6320 5422 5103 5056 5047>,
			<7091 6371 5455 5105 5049 5039>,
			<7123 6425 5487 5107 5048 5038>,
			<7155 6480 5518 5110 5049 5039>,
			<7187 6540 5550 5113 5050 5040>,
			<7223 6603 5584 5120 5052 5042>,
			<7261 6670 5619 5129 5054 5043>,
			<7306 6743 5663 5135 5054 5043>,
			<7362 6823 5719 5140 5054 5040>,
			<7432 6913 5789 5149 5055 5040>,
			<7531 7021 5885 5166 5064 5049>,
			<7591 7075 5946 5180 5072 5059>,
			<7663 7130 6012 5192 5086 5075>,
			<7697 7152 6021 5201 5096 5087>,
			<7665 7045 5984 5222 5101 5078>,
			<7717 7016 5994 5221 5074 5055>,
			<7810 7082 6019 5211 5076 5055>,
			<7930 7188 6092 5235 5086 5063>,
			<8133 7354 6230 5272 5105 5079>,
			<8133 7354 6230 5272 5105 5079>,
			<8133 7354 6230 5272 5105 5079>;
	};
};
